# csi_rx_if0_RX_SHIM_VBUSP_MMR_CSI2RXIF register map
Vendor: Texas Instruments
Peripheral module from a debugger description file (folder J721S2).
Registers are 32-bit, read-write, reset 0x0 unless marked. A register's access mark holds for its fields unless they carry their own. Offsets are as the file gives them; lines under a group give offsets from that group; [hi:lo] are bit positions; {n}, {i} and the like mark numbered series; 'fields as' and 'values as' point back to an identical list; <NAME> marks a mode.

## csi_rx_if0_RX_SHIM_VBUSP_MMR_CSI2RXIF
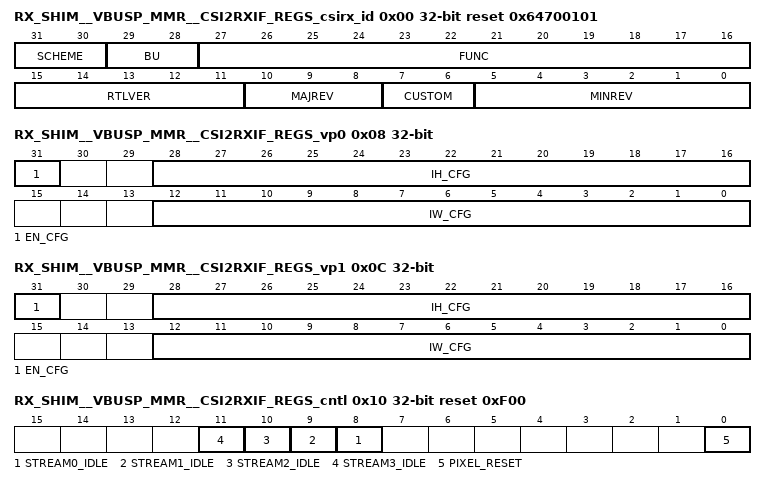
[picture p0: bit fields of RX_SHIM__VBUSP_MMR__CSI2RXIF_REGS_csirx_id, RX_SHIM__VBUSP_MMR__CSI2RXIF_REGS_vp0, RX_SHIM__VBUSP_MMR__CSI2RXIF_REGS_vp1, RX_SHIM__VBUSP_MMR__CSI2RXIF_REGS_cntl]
0x00 RX_SHIM__VBUSP_MMR__CSI2RXIF_REGS_csirx_id ro reset 0x64700101 — nothing
  [31:30] SCHEME
  [29:28] BU
  [27:16] FUNC — function
  [15:11] RTLVER — rtl version
  [10:8] MAJREV — major revision
  [7:6] CUSTOM — custom revision
  [5:0] MINREV — min revision
0x08 RX_SHIM__VBUSP_MMR__CSI2RXIF_REGS_vp0 — Video Port 0 configuration
  [31] EN_CFG — Video Port enable. Disable:drops pixel data Enable: start on VS, captures and sends frame data. Will force ih and iw size by zero pad or trunc. When 1 prevents writing rest of fields in this register.
  [28:16] IH_CFG — (U13) input height in units of lines. Only writable when vp0_en_cfg=0. writes blockes when vp0_en_cfg=1
  [12:0] IW_CFG — (U13) input width in units of RAW data samples. Max usable value determined by populated line buffer RAM size. Only writable when vp0_en_cfg=0. writes blockes when vp0_en_cfg=1. You should read this value first and if set to 0 then you should write the height/width values.
0x0C RX_SHIM__VBUSP_MMR__CSI2RXIF_REGS_vp1 — Video Port 1 configuration
  [31] EN_CFG — Video Port enable. Disable:drops pixel data Enable: start on VS, captures and sends frame data. Will force ih and iw size by zero pad or trunc. When 1 prevents writing rest of fields in this register.
  [28:16] IH_CFG — (U13) input height in units of lines. Only writable when vp0_en_cfg=0. writes blovkes when vp1_en_cfg=1
  [12:0] IW_CFG — (U13) input width in units of RAW data samples. Max usable value determined by populated line buffer RAM size. Only writable when vp1_en_cfg=0. writes blockes when vp1_en_cfg=1. You should read this value first and if set to 0 then you should write the height/width values.
0x10 RX_SHIM__VBUSP_MMR__CSI2RXIF_REGS_cntl access per field reset 0xF00 — control register for csi rx wrapper
  [n+8] STREAM{n}_IDLE ro (n=0..3) — indicates if stream interface is idle(1) or not(0)
  [0] PIXEL_RESET rw — reset for the pixeal interface. 0-reset, 1 not in reset. this shoud be asserted till after you program the csi controller configuration registers
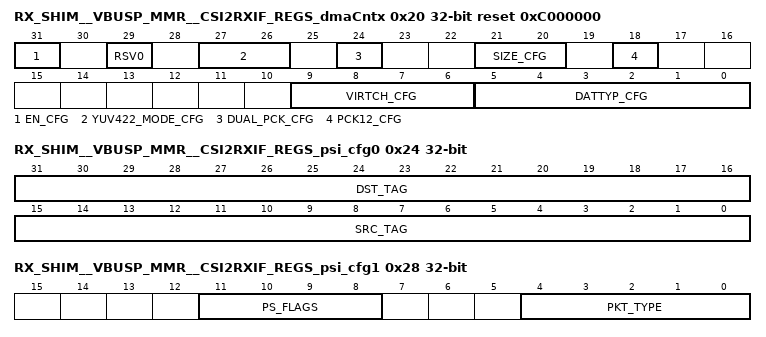
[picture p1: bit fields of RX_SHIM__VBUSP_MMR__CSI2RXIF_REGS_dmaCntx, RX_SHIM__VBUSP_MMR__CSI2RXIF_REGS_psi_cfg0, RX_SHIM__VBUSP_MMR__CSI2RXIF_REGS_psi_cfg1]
0x20 RX_SHIM__VBUSP_MMR__CSI2RXIF_REGS_dmaCntx reset 0xC000000 — DMA Channel Context. Configuration for each of 32 possible channel contexts. Illegal to program 2 chanCntx with same extraction values.
  [31] EN_CFG — DMA context is enabled. Will extract channel if input matches dataType and VirtualChan
  [29] RSV0 — reserved
  [27:26] YUV422_MODE_CFG — yuv422 mode 00:UYVY, 01:VYUY, 10:YUYV, 11:YVYU
  [24] DUAL_PCK_CFG — dual packed format extraction for 8 bits or less
  [21:20] SIZE_CFG — data size shift when unpacking, 00=8, 01=16, 10=32, 11=RSVD
  [18] PCK12_CFG — 12-bit packing enable
  [9:6] VIRTCH_CFG — CSI virtual channel index. Supplied by MIPI CSI protocol to DPHY. For CSIver1.3 program 2MSb==0
  [5:0] DATTYP_CFG — CSI data type index. Supplied by MIPI CSI protocol to DPHY
0x24 RX_SHIM__VBUSP_MMR__CSI2RXIF_REGS_psi_cfg0 — psi configuration register0
  [31:16] DST_TAG — psi dst tag
  [15:0] SRC_TAG — psi source tag
0x28 RX_SHIM__VBUSP_MMR__CSI2RXIF_REGS_psi_cfg1 — psi configuration register1
  [11:8] PS_FLAGS
  [4:0] PKT_TYPE — psi packet type
